# STM32F446 register map
File version: 1.1
CPU: CM4 r1p0, little endian, no MPU, no FPU, 4 interrupt priority bits
Registers are 32-bit, read-write, reset 0x0 unless marked. A register's access mark holds for its fields unless they carry their own. Offsets are from the block's base; [hi:lo] are bit positions; {n}, {i} and the like mark numbered series.

## OTG_HS_DEVICE — USB on the go high speed
Base 0x40040800
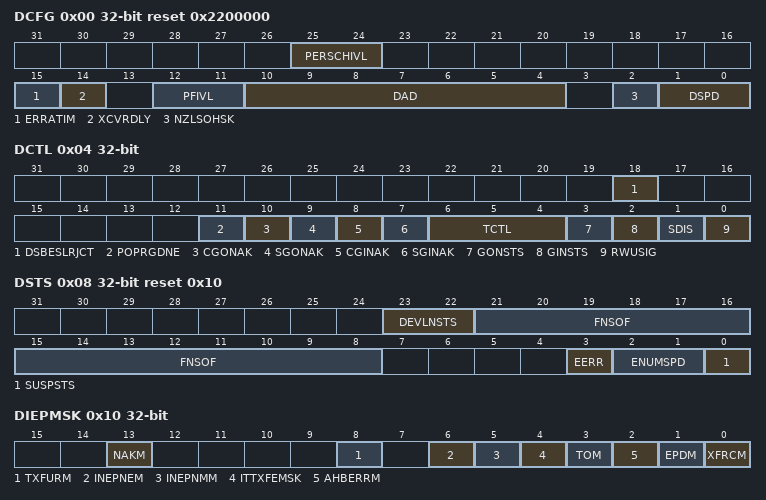
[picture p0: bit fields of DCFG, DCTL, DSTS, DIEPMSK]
0x00 DCFG reset 0x2200000 — OTG device configuration register
  [25:24] PERSCHIVL — Periodic scheduling interval
  [15] ERRATIM — Erratic error interrupt mask
  [14] XCVRDLY — Transceiver delay
  [12:11] PFIVL — Periodic frame interval
  [10:4] DAD — Device address
  [2] NZLSOHSK — Non-zero-length status OUT handshake
  [1:0] DSPD — Device speed
0x04 DCTL access per field — OTG device control register
  [18] DSBESLRJCT rw — Deep sleep BESL reject
  [11] POPRGDNE rw — Power-on programming done
  [10] CGONAK wo — Clear global OUT NAK
  [9] SGONAK wo — Set global OUT NAK
  [8] CGINAK wo — Clear global IN NAK
  [7] SGINAK wo — Set global IN NAK
  [6:4] TCTL rw — Test control
  [3] GONSTS ro — Global OUT NAK status
  [2] GINSTS ro — Global IN NAK status
  [1] SDIS rw — Soft disconnect
  [0] RWUSIG rw — Remote wakeup signaling
0x08 DSTS ro reset 0x10 — OTG device status register
  [23:22] DEVLNSTS — Device line status
  [21:8] FNSOF — Frame number of the received SOF
  [3] EERR — Erratic error
  [2:1] ENUMSPD — Enumerated speed
  [0] SUSPSTS — Suspend status
0x10 DIEPMSK — OTG device IN endpoint common interrupt mask register
  [13] NAKM — NAK interrupt mask
  [8] TXFURM — FIFO underrun mask
  [6] INEPNEM — IN endpoint NAK effective mask
  [5] INEPNMM — IN token received with EP mismatch mask
  [4] ITTXFEMSK — IN token received when Tx FIFO empty mask
  [3] TOM — Timeout condition mask (Non-isochronous endpoints)
  [2] AHBERRM — AHB error mask
  [1] EPDM — Endpoint disabled interrupt mask
  [0] XFRCM — Transfer completed interrupt mask
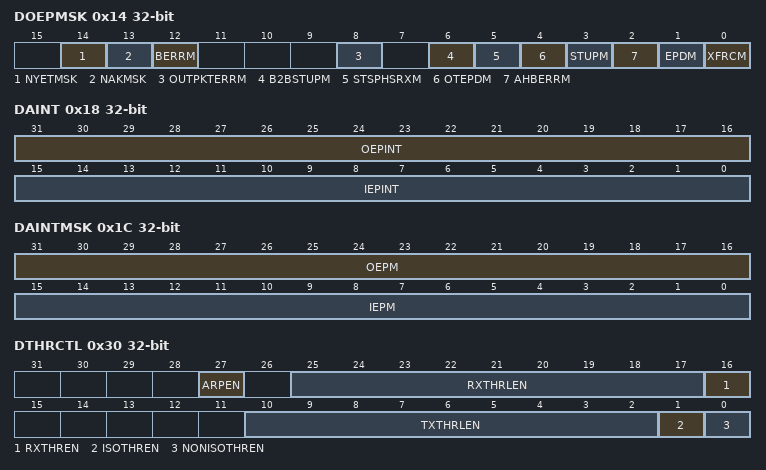
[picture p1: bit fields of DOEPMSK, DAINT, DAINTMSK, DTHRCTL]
0x14 DOEPMSK — OTG device OUT endpoint common interrupt mask register
  [14] NYETMSK — NYET interrupt mask
  [13] NAKMSK — NAK interrupt mask
  [12] BERRM — Babble error interrupt mask
  [8] OUTPKTERRM — OUT packet error mask
  [6] B2BSTUPM — Back-to-back SETUP packets received mask
  [5] STSPHSRXM — Status phase received for control write mask
  [4] OTEPDM — OUT token received when endpoint disabled mask
  [3] STUPM — SETUP phase done mask
  [2] AHBERRM — AHB error mask
  [1] EPDM — Endpoint disabled interrupt mask
  [0] XFRCM — Transfer completed interrupt mask
0x18 DAINT ro — OTG device all endpoints interrupt register
  [31:16] OEPINT — OUT endpoint interrupt bits
  [15:0] IEPINT — IN endpoint interrupt bits
0x1C DAINTMSK — OTG all endpoints interrupt mask register
  [31:16] OEPM — OUT EP interrupt mask bits
  [15:0] IEPM — IN EP interrupt mask bits
0x28 DVBUSDIS reset 0x17D7 — OTG device VBUS discharge time register
  [15:0] VBUSDT — Device VBUS discharge time
0x2C DVBUSPULSE reset 0x5B8 — OTG device VBUS pulsing time register
  [11:0] DVBUSP — Device VBUS pulsing time
0x30 DTHRCTL — OTG device threshold control register
  [27] ARPEN — Arbiter parking enable
  [25:17] RXTHRLEN — Receive threshold length
  [16] RXTHREN — Receive threshold enable
  [10:2] TXTHRLEN — Transmit threshold length
  [1] ISOTHREN — ISO IN endpoint threshold enable
  [0] NONISOTHREN — Nonisochronous IN endpoints threshold enable
0x34 DIEPEMPMSK — OTG device IN endpoint FIFO empty interrupt mask register
  [15:0] INEPTXFEM — IN EP Tx FIFO empty interrupt mask bits
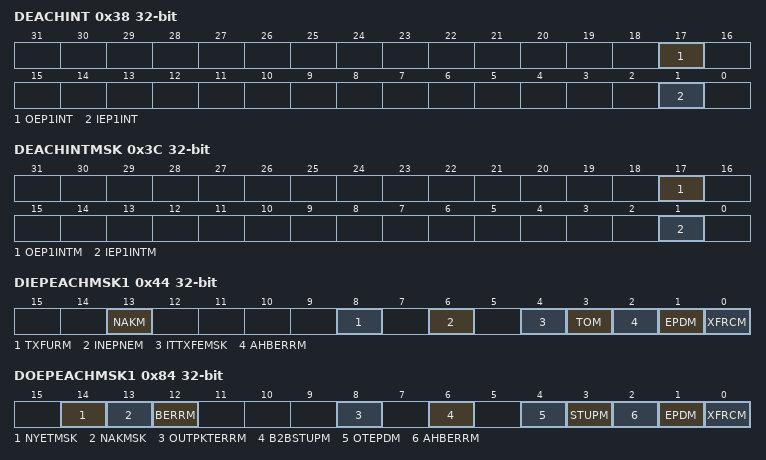
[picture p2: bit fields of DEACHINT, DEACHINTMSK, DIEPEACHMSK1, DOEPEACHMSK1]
0x38 DEACHINT ro — OTG device each endpoint interrupt register
  [17] OEP1INT — OUT endpoint 1 interrupt bit
  [1] IEP1INT — IN endpoint 1interrupt bit
0x3C DEACHINTMSK — OTG device each endpoint interrupt mask register
  [17] OEP1INTM — OUT Endpoint 1 interrupt mask bit
  [1] IEP1INTM — IN Endpoint 1 interrupt mask bit
0x44 DIEPEACHMSK1 — OTG device each IN endpoint-1 interrupt mask register
  [13] NAKM — NAK interrupt mask
  [8] TXFURM — FIFO underrun mask
  [6] INEPNEM — IN endpoint NAK effective mask
  [4] ITTXFEMSK — IN token received when Tx FIFO empty mask
  [3] TOM — Timeout condition mask (Non-isochronous endpoints)
  [2] AHBERRM — AHB error mask
  [1] EPDM — Endpoint disabled interrupt mask
  [0] XFRCM — Transfer completed interrupt mask
0x84 DOEPEACHMSK1 — OTG device each OUT endpoint-1 interrupt mask register
  [14] NYETMSK — NYET interrupt mask
  [13] NAKMSK — NAK interrupt mask
  [12] BERRM — Babble error interrupt mask
  [8] OUTPKTERRM — OUT packet error mask
  [6] B2BSTUPM — Back-to-back SETUP packets received mask
  [4] OTEPDM — OUT token received when endpoint disabled mask
  [3] STUPM — SETUP phase done mask
  [2] AHBERRM — AHB error mask
  [1] EPDM — Endpoint disabled interrupt mask
  [0] XFRCM — Transfer completed interrupt mask
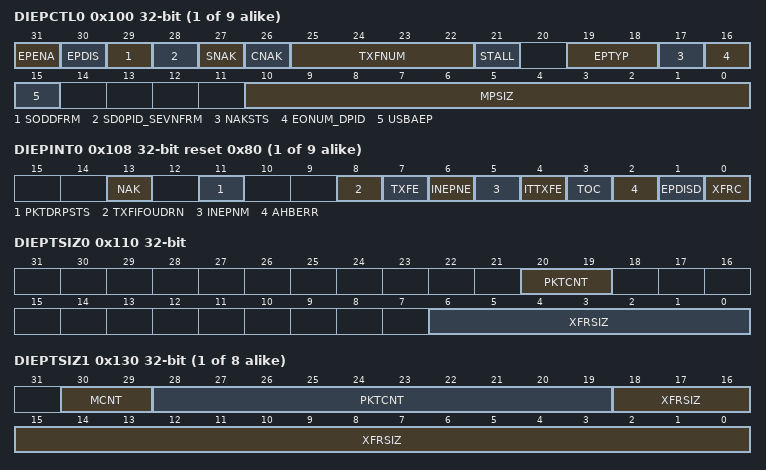
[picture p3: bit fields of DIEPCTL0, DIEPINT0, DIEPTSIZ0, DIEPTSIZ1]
{0x100+0x20*i} DIEPCTL{i} (i=0..8) access per field — OTG device IN endpoint x control register
  [31] EPENA rw — Endpoint enable
  [30] EPDIS rw — Endpoint disable
  [29] SODDFRM wo — Set odd frame
  [28] SD0PID_SEVNFRM wo — Set DATA0 PID / Set even frame
  [27] SNAK wo — Set NAK
  [26] CNAK wo — Clear NAK
  [25:22] TXFNUM rw — Tx FIFO number
  [21] STALL rw — STALL handshake
  [19:18] EPTYP rw — Endpoint type
  [17] NAKSTS ro — NAK status
  [16] EONUM_DPID ro — Even/odd frame / Endpoint data PID
  [15] USBAEP rw — USB active endpoint
  [10:0] MPSIZ rw — Maximum packet size
{0x108+0x20*i} DIEPINT{i} (i=0..8) access per field reset 0x80 — OTG device IN endpoint x interrupt register
  [13] NAK rw — NAK interrupt
  [11] PKTDRPSTS rw — Packet dropped status
  [8] TXFIFOUDRN rw — Transmit FIFO underrun
  [7] TXFE ro — Transmit FIFO empty
  [6] INEPNE rw — IN endpoint NAK effective
  [5] INEPNM rw — IN token received with EP mismatch
  [4] ITTXFE rw — IN token received when Tx FIFO is empty
  [3] TOC rw — Timeout condition
  [2] AHBERR rw — AHB error
  [1] EPDISD rw — Endpoint disabled interrupt
  [0] XFRC rw — Transfer completed interrupt
0x110 DIEPTSIZ0 — OTG device IN endpoint 0 transfer size register
  [20:19] PKTCNT — Packet count
  [6:0] XFRSIZ — Transfer size
{0x114+0x20*i} DIEPDMA{i} (i=0..8) — OTG device IN endpoint x DMA address register
  [31:0] DMAADDR — DMA address
{0x118+0x20*i} DTXFSTS{i} (i=0..8) ro — OTG device IN endpoint transmit FIFO status register
  [15:0] INEPTFSAV — IN endpoint Tx FIFO space available
{0x110+0x20*i} DIEPTSIZ{i} (i=1..8) — OTG device IN endpoint x transfer size register
  [30:29] MCNT — Multi count
  [28:19] PKTCNT — Packet count
  [18:0] XFRSIZ — Transfer size
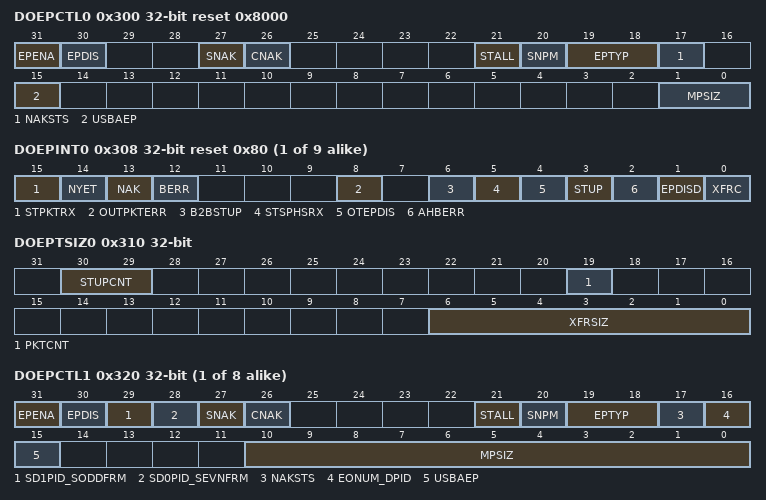
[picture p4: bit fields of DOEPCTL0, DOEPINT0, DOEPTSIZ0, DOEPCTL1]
0x300 DOEPCTL0 access per field reset 0x8000 — OTG device control OUT endpoint 0 control register
  [31] EPENA wo — Endpoint enable
  [30] EPDIS ro — Endpoint disable
  [27] SNAK wo — Set NAK
  [26] CNAK wo — Clear NAK
  [21] STALL rw — STALL handshake
  [20] SNPM rw — Snoop mode
  [19:18] EPTYP ro — Endpoint type
  [17] NAKSTS ro — NAK status
  [15] USBAEP ro — USB active endpoint
  [1:0] MPSIZ ro — Maximum packet size
{0x308+0x20*i} DOEPINT{i} (i=0..8) reset 0x80 — OTG device OUT endpoint x interrupt register
  [15] STPKTRX — Setup packet received
  [14] NYET — NYET interrupt
  [13] NAK — NAK input
  [12] BERR — Babble error interrupt
  [8] OUTPKTERR — OUT packet error
  [6] B2BSTUP — Back-to-back SETUP packets received
  [5] STSPHSRX — Status phase received for control write
  [4] OTEPDIS — OUT token received when endpoint disabled
  [3] STUP — SETUP phase done
  [2] AHBERR — AHB error
  [1] EPDISD — Endpoint disabled interrupt
  [0] XFRC — Transfer completed interrupt
0x310 DOEPTSIZ0 — OTG device OUT endpoint 0 transfer size register
  [30:29] STUPCNT — SETUP packet count
  [19] PKTCNT — Packet count
  [6:0] XFRSIZ — Transfer size
{0x314+0x20*i} DOEPDMA{i} (i=0..8) — OTG device OUT endpoint x DMA address register
  [31:0] DMAADDR — DMA address
{0x300+0x20*i} DOEPCTL{i} (i=1..8) access per field — OTG device OUT endpoint x control register
  [31] EPENA rw — Endpoint enable
  [30] EPDIS rw — Endpoint disable
  [29] SD1PID_SODDFRM wo — Set DATA1 PID/Set odd frame
  [28] SD0PID_SEVNFRM wo — Set DATA0 PID/Set even frame
  [27] SNAK wo — Set NAK
  [26] CNAK wo — Clear NAK
  [21] STALL rw — STALL handshake
  [20] SNPM rw — Snoop mode
  [19:18] EPTYP rw — Endpoint type
  [17] NAKSTS ro — NAK status
  [16] EONUM_DPID ro — Even odd frame/Endpoint data PID
  [15] USBAEP rw — USB active endpoint
  [10:0] MPSIZ rw — Maximum packet size
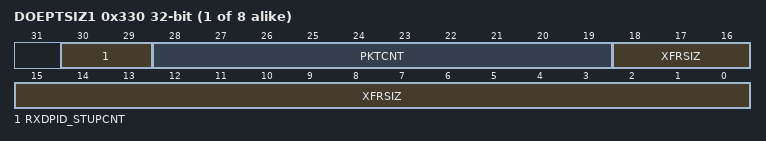
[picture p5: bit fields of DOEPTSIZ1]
{0x310+0x20*i} DOEPTSIZ{i} (i=1..8) — OTG device OUT endpoint x transfer size register
  [30:29] RXDPID_STUPCNT — Received data PID/SETUP packet count
  [28:19] PKTCNT — Packet count
  [18:0] XFRSIZ — Transfer size
